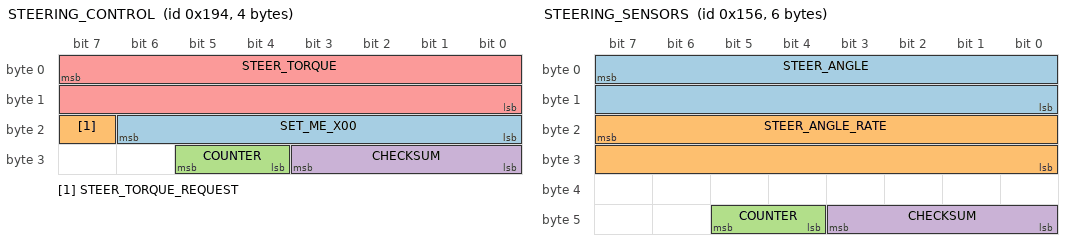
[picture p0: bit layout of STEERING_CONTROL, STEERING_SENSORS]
BO_ 404 STEERING_CONTROL: 4 EON
 SG_ SET_ME_X00 : 22|7@0+ (1,0) [0|127] "" EPS
 SG_ STEER_TORQUE_REQUEST : 23|1@0+ (1,0) [0|1] "" EPS
 SG_ COUNTER : 29|2@0+ (1,0) [0|15] "" EPS
 SG_ CHECKSUM : 27|4@0+ (1,0) [0|3] "" EPS
 SG_ STEER_TORQUE : 7|16@0- (-1,0) [-32767|32767] "" EPS

BO_ 342 STEERING_SENSORS: 6 EPS
 SG_ STEER_ANGLE : 7|16@0- (-0.1,0) [-500|500] "deg" EON
 SG_ STEER_ANGLE_RATE : 23|16@0- (-1,0) [-3000|3000] "deg/s" EON
 SG_ COUNTER : 45|2@0+ (1,0) [0|3] "" EON
 SG_ CHECKSUM : 43|4@0+ (1,0) [0|15] "" EON

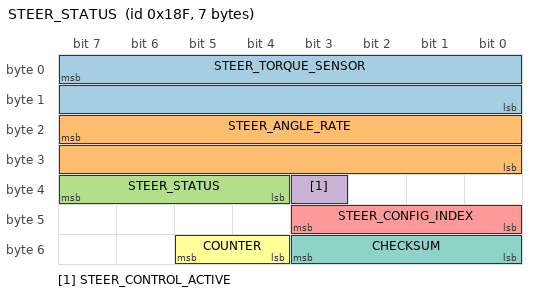
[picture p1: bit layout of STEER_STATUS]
BO_ 399 STEER_STATUS: 7 EPS
 SG_ STEER_TORQUE_SENSOR : 7|16@0- (-1,0) [-31000|31000] "tbd" EON
 SG_ STEER_ANGLE_RATE : 23|16@0- (-0.1,0) [-31000|31000] "deg/s" EON
 SG_ STEER_STATUS : 39|4@0+ (1,0) [0|15] "" EON
 SG_ STEER_CONTROL_ACTIVE : 35|1@0+ (1,0) [0|1] "" EON
 SG_ STEER_CONFIG_INDEX : 43|4@0+ (1,0) [0|15] "" EON
 SG_ COUNTER : 53|2@0+ (1,0) [0|3] "" EON
 SG_ CHECKSUM : 51|4@0+ (1,0) [0|3] "" EON
